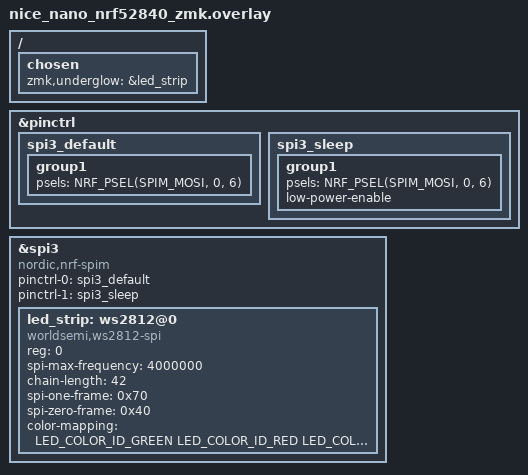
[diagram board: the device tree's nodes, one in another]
/*
 * mami42 - nice_nano/nrf52840/zmk 用のRGBアンダーグロー(per-key)設定
 *
 * PCB上にSK6812MINI-E(WS2812互換)が42個(L1〜L42, 各キー1個)搭載されており、
 * データラインはnice!nanoのP0.06(pad1, ネット名"LED")から
 * L1 -> L2 -> ... -> L42 の順に一直線にデイジーチェーン接続されている
 * (cad/mami.kicad_pcb のネット情報で確認済み)。
 */

#include <dt-bindings/led/led.h>

&pinctrl {
    spi3_default: spi3_default {
        group1 {
            psels = <NRF_PSEL(SPIM_MOSI, 0, 6)>;
        };
    };

    spi3_sleep: spi3_sleep {
        group1 {
            psels = <NRF_PSEL(SPIM_MOSI, 0, 6)>;
            low-power-enable;
        };
    };
};

&spi3 {
    compatible = "nordic,nrf-spim";
    status = "okay";

    pinctrl-0 = <&spi3_default>;
    pinctrl-1 = <&spi3_sleep>;
    pinctrl-names = "default", "sleep";

    led_strip: ws2812@0 {
        compatible = "worldsemi,ws2812-spi";

        /* SPI */
        reg = <0>; /* ignored, but necessary for SPI bindings */
        spi-max-frequency = <4000000>;

        /* WS2812 */
        chain-length = <42>; /* L1〜L42 (キー1個につきLED1個) */
        spi-one-frame = <0x70>;
        spi-zero-frame = <0x40>;
        color-mapping = <LED_COLOR_ID_GREEN
                         LED_COLOR_ID_RED
                         LED_COLOR_ID_BLUE>;
    };
};

/ {
    chosen {
        zmk,underglow = &led_strip;
    };
};
